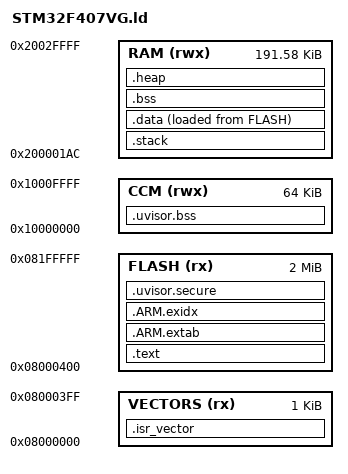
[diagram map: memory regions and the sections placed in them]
/*
 * PackageLicenseDeclared: Apache-2.0
 * Copyright (c) 2015 ARM Limited
 *
 * Licensed under the Apache License, Version 2.0 (the "License");
 * you may not use this file except in compliance with the License.
 * You may obtain a copy of the License at
 *
 *     http://www.apache.org/licenses/LICENSE-2.0
 *
 * Unless required by applicable law or agreed to in writing, software
 * distributed under the License is distributed on an "AS IS" BASIS,
 * WITHOUT WARRANTIES OR CONDITIONS OF ANY KIND, either express or implied.
 * See the License for the specific language governing permissions and
 * limitations under the License.
 */
/* Linker script to configure memory regions. */
MEMORY
{
  VECTORS (rx)          : ORIGIN = 0x08000000, LENGTH = 0x00000400
  FLASH (rx)            : ORIGIN = 0x08000400, LENGTH = 2048k - 0x400
  CCM (rwx)             : ORIGIN = 0x10000000, LENGTH = 64K
  RAM (rwx)             : ORIGIN = 0x200001AC, LENGTH = 192k - 0x1AC
}

/* Linker script to place sections and symbol values. Should be used together
 * with other linker script that defines memory regions FLASH and RAM.
 * It references following symbols, which must be defined in code:
 *   Reset_Handler : Entry of reset handler
 *
 * It defines following symbols, which code can use without definition:
 *   __exidx_start
 *   __exidx_end
 *   __etext
 *   __data_start__
 *   __preinit_array_start
 *   __preinit_array_end
 *   __init_array_start
 *   __init_array_end
 *   __fini_array_start
 *   __fini_array_end
 *   __data_end__
 *   __bss_start__
 *   __bss_end__
 *   __end__
 *   end
 *   __HeapLimit
 *   __StackLimit
 *   __StackTop
 *   __stack
 *   _estack
 */
ENTRY(Reset_Handler)

SECTIONS
{
    .isr_vector :
    {
        __vector_table = .;
        KEEP(*(.isr_vector))
         . = ALIGN(4);
    } > VECTORS

    /* ensure that uvisor bss is at the beginning of memory */
    .uvisor.bss (NOLOAD):
    {
        . = ALIGN(32);
        __uvisor_bss_start = .;

        /* protected uvisor main bss */
        . = ALIGN(32);
        __uvisor_bss_main_start = .;
        KEEP(*(.keep.uvisor.bss.main))
        . = ALIGN(32);
        __uvisor_bss_main_end = .;

        /* protected uvisor secure boxes bss */
        . = ALIGN(32);
        __uvisor_bss_boxes_start = .;
        KEEP(*(.keep.uvisor.bss.boxes))
        . = ALIGN(32);
        __uvisor_bss_boxes_end = .;

        . = ALIGN(32);
        __uvisor_bss_end = .;
    } > CCM

    .text :
    {
        /* uVisor code and data */
        . = ALIGN(4);
        __uvisor_main_start = .;
        *(.uvisor.main)
        __uvisor_main_end = .;

        *(.text*)

        KEEP(*(.init))
        KEEP(*(.fini))

        /* .ctors */
        *crtbegin.o(.ctors)
        *crtbegin?.o(.ctors)
        *(EXCLUDE_FILE(*crtend?.o *crtend.o) .ctors)
        *(SORT(.ctors.*))
        *(.ctors)

        /* .dtors */
        *crtbegin.o(.dtors)
        *crtbegin?.o(.dtors)
        *(EXCLUDE_FILE(*crtend?.o *crtend.o) .dtors)
        *(SORT(.dtors.*))
        *(.dtors)

        *(.rodata*)

        KEEP(*(.eh_frame*))
    } > FLASH

    .ARM.extab :
    {
        *(.ARM.extab* .gnu.linkonce.armextab.*)
    } > FLASH

    __exidx_start = .;

    .ARM.exidx :
    {
        *(.ARM.exidx* .gnu.linkonce.armexidx.*)
    } > FLASH
    __exidx_end = .;

    __etext = .;
    _sidata = .;

    /* .stack section doesn't contains any symbols. It is only
     * used for linker to reserve space for the main stack section
     * WARNING: .stack should come immediately after the last secure memory
     * section.  This provides stack overflow detection. */
    .stack (NOLOAD):
    {
        __StackLimit = .;
        *(.stack*);
        . += 0x8000 - (. - __StackLimit);
    } > RAM

    /* Set stack top to end of RAM, and stack limit move down by
     * size of stack_dummy section */
    __StackTop = ADDR(.stack) + SIZEOF(.stack);
    __StackLimit = ADDR(.stack);
    PROVIDE(__stack = __StackTop);

    .data :
    {
        PROVIDE( __etext = LOADADDR(.data) );

        __data_start__ = .;
        _sdata = .;
        *(vtable)
        *(.data*)

        . = ALIGN(4);
        /* preinit data */
        PROVIDE_HIDDEN (__preinit_array_start = .);
        KEEP(*(.preinit_array))
        PROVIDE_HIDDEN (__preinit_array_end = .);

        . = ALIGN(4);
        /* init data */
        PROVIDE_HIDDEN (__init_array_start = .);
        KEEP(*(SORT(.init_array.*)))
        KEEP(*(.init_array))
        PROVIDE_HIDDEN (__init_array_end = .);


        . = ALIGN(4);
        /* finit data */
        PROVIDE_HIDDEN (__fini_array_start = .);
        KEEP(*(SORT(.fini_array.*)))
        KEEP(*(.fini_array))
        PROVIDE_HIDDEN (__fini_array_end = .);

        KEEP(*(.jcr*))
        . = ALIGN(4);
        /* All data end */
        __data_end__ = .;
        _edata = .;

    } > RAM AT>FLASH

    /* uvisor configuration data */
    .uvisor.secure :
    {
        . = ALIGN(32);
        __uvisor_secure_start = .;

        /* uvisor secure boxes configuration tables */
        . = ALIGN(32);
        __uvisor_cfgtbl_start = .;
        KEEP(*(.keep.uvisor.cfgtbl))
        . = ALIGN(32);
        __uvisor_cfgtbl_end = .;

        /* pointers to uvisor secure boxes configuration tables */
        /* note: no further alignment here, we need to have the exact list of pointers */
        __uvisor_cfgtbl_ptr_start = .;
        KEEP(*(.keep.uvisor.cfgtbl_ptr_first))
        KEEP(*(.keep.uvisor.cfgtbl_ptr))
        __uvisor_cfgtbl_ptr_end = .;

        /* the following symbols are kept for backward compatibility and will be soon
         * deprecated; applications actively using uVisor (__uvisor_mode == UVISOR_ENABLED)
         * will need to use uVisor 0.8.x or above, or the security assertions will halt the
         * system */
        /************************/
        __uvisor_data_src = .;
        __uvisor_data_start = .;
        __uvisor_data_end = .;
        /************************/

        . = ALIGN(32);
        __uvisor_secure_end = .;
    } >FLASH

    .bss (NOLOAD):
    {
        . = ALIGN(4);
        __bss_start__ = .;
        _sbss = .;
        *(.bss*)
        *(COMMON)
        . = ALIGN(4);
        __bss_end__ = .;
        _ebss = .;
    } > RAM

    .heap (NOLOAD):
    {
        __end__ = .;
        end = __end__;
        *(.heap*);
        . += (ORIGIN(RAM) + LENGTH(RAM) - .);
        __HeapLimit = .;
    } > RAM
    PROVIDE(__heap_size = SIZEOF(.heap));
    PROVIDE(__mbed_sbrk_start = ADDR(.heap));
    PROVIDE(__mbed_krbs_start = ADDR(.heap) + SIZEOF(.heap));
}
